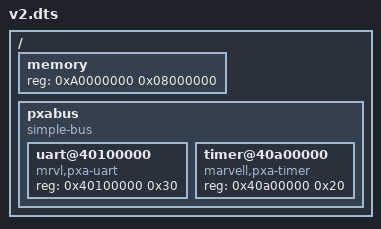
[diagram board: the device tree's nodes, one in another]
/* ### START: full */
/dts-v1/;

/ {
    #address-cells = <1>;
    #size-cells = <1>;

    memory {
        device_type = "memory";
        reg = <0xA0000000 0x08000000>;
    };

    /* ### START: peripherals */
    pxabus {
        compatible = "simple-bus";
        #address-cells = <1>;
        #size-cells = <1>;
        ranges;

        uart@40100000 {
            compatible = "mrvl,pxa-uart";
            reg = <0x40100000 0x30>;
        };

        timer@40a00000 {
            compatible = "marvell,pxa-timer";
            reg = <0x40a00000 0x20>;
        };
    };
    /* ### END: peripherals */
};
/* ### END: full */
